# RZT2L register map
Vendor: Renesas Electronics Corporation; Series: RZT; File version: 1.20.00
CPU: other r0p0, little endian, MPU, no FPU, VTOR, 4 interrupt priority bits, 624 interrupts
Registers are 32-bit, read-write, reset 0x0 unless marked. A register's access mark holds for its fields unless they carry their own. Offsets are from the block's base; [hi:lo] are bit positions; {n}, {i} and the like mark numbered series; 'fields as' and 'values as' point back to an identical list.

## CANFD (part 2 of 2)
Base 0x80020000
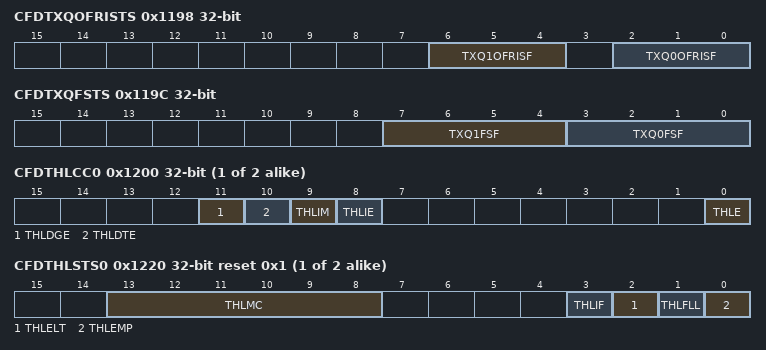
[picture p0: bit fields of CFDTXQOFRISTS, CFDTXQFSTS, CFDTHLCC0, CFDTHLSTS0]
0x1198 CFDTXQOFRISTS ro — TX Queue One Frame RX Interrupt Status Register
  [6:4] TXQ1OFRISF — TXQ One Frame RX Interrupt Status Flag for Channel 1
    0=TXQ One Frame RX Interrupt flag not set; 1=TXQ One Frame RX Interrupt flag set
  [2:0] TXQ0OFRISF — TXQ One Frame RX Interrupt Status Flag for Channel 0
    values as TXQ1OFRISF
0x119C CFDTXQFSTS ro — TX Queue Full Status Register
  [7:4] TXQ1FSF — TXQ Full Status Flag for Channel 1
    0=TXQ Full flag not set; 1=TXQ Full flag set
  [3:0] TXQ0FSF — TXQ Full Status Flag for Channel 0
    0=TXQ Full flag not set; 1=TXQ Full flag set
{0x1200+4i} CFDTHLCC{i} (i=0..1) — TX History List Configuration/Control Register {i}
  [11] THLDGE — TX History List Dedicated Gateway Enable
    0=Not dedicated Gateway FIFO + Gateway TX Queue; 1=Dedicated Gateway FIFO + Gateway TX Queue
  [10] THLDTE — TX History List Dedicated TX Enable
    0=TX FIFO + TX Queue; 1=Flat TX MB + TX FIFO + TX Queue
  [9] THLIM — TX History List Interrupt Mode
    0=Interrupt generated if TX History List level reaches 3/4 of the TX History List depth; 1=Interrupt generated for every successfully stored entry
  [8] THLIE — TX History List Interrupt Enable
    0=TX History List Interrupt disabled; 1=TX History List Interrupt enabled
  [0] THLE — TX History List Enable
    0=TX History List disabled; 1=TX History List enabled
{0x1220+4i} CFDTHLSTS{i} (i=0..1) reset 0x1 — TX History List Status Register {i}
  [13:8] THLMC ro — TX History List Message Count
  [3] THLIF — TX History List Interrupt Flag
    0=TX History List interrupt condition not satisfied; 1=TX History List interrupt condition satisfied
  [2] THLELT — TX History List Entry Lost
    0=No entry lost in TX History List; 1=TX History List entry Lost
  [1] THLFLL ro — TX History List Full
    0=TX History List not full; 1=TX History List full
  [0] THLEMP ro — TX History List Empty
    0=TX History List not empty; 1=TX History List empty
{0x1240+4i} CFDTHLPCTR{i} (i=0..1) wo — TX History List Pointer Control Register {i}
  [7:0] THLPC — TX History List Pointer Control
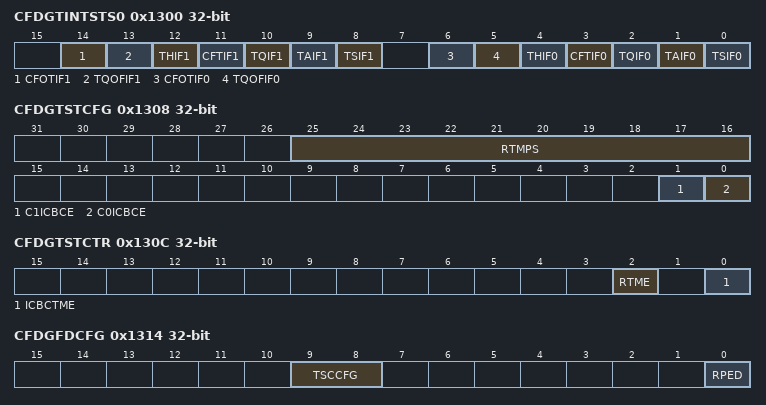
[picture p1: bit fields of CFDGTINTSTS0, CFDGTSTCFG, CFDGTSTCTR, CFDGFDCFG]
0x1300 CFDGTINTSTS0 ro — Global TX Interrupt Status Register 0
  [14] CFOTIF1 — COM FIFO One Frame Transmission Interrupt Flag Channel 1
    0=Channel 1 COM FIFO One Frame Transmission Interrupt flag not set; 1=Channel 1 COM FIFO One Frame Transmission Interrupt flag set
  [13] TQOFIF1 — TX Queue One Frame Transmission Interrupt Flag Channel 1
    0=Channel 1 TX Queue One Frame Transmission Interrupt flag not set; 1=Channel 1 TX Queue One Frame Transmission Interrupt flag set
  [12] THIF1 — TX History List Interrupt Channel 1
    0=Channel 1 TX History List Interrupt flag not set; 1=Channel 1 TX History List Interrupt flag set
  [11] CFTIF1 — COM FIFO TX/GW Mode Interrupt Flag Channel 1
    0=Channel 1 COM FIFO TX/GW Mode Interrupt flag not set; 1=Channel 1 COM FIFO TX/GW Mode Interrupt flag set
  [10] TQIF1 — TX Queue Interrupt Flag Channel 1
    0=Channel 1 TX Queue Interrupt flag not set; 1=Channel 1 TX Queue Interrupt flag set
  [9] TAIF1 — TX Abort Interrupt Flag Channel 1
    0=Channel 1 TX Abort Interrupt flag not set; 1=Channel 1 TX Abort Interrupt flag set
  [8] TSIF1 — TX Successful Interrupt Flag Channel 1
    0=Channel 1 TX Successful Interrupt flag not set; 1=Channel 1 TX Successful Interrupt flag set
  [6] CFOTIF0 — COM FIFO One Frame Transmission Interrupt Flag Channel 0
    0=Channel 0 COM FIFO One Frame Transmission Interrupt flag not set; 1=Channel 0 COM FIFO One Frame Transmission Interrupt flag set
  [5] TQOFIF0 — TX Queue One Frame Transmission Interrupt Flag Channel 0
    0=Channel 0 TX Queue One Frame Transmission Interrupt flag not set; 1=Channel 0 TX Queue One Frame Transmission Interrupt flag set
  [4] THIF0 — TX History List Interrupt Channel 0
    0=Channel 0 TX History List Interrupt flag not set; 1=Channel 0 TX History List Interrupt flag set
  [3] CFTIF0 — COM FIFO TX/GW Mode Interrupt Flag Channel 0
    0=Channel 0 COM FIFO TX/GW Mode Interrupt flag not set; 1=Channel 0 COM FIFO TX/GW Mode Interrupt flag set
  [2] TQIF0 — TX Queue Interrupt Flag Channel 0
    0=Channel 0 TX Queue Interrupt flag not set; 1=Channel 0 TX Queue Interrupt flag set
  [1] TAIF0 — TX Abort Interrupt Flag Channel 0
    0=Channel 0 TX Abort Interrupt flag not set; 1=Channel 0 TX Abort Interrupt flag set
  [0] TSIF0 — TX Successful Interrupt Flag Channel 0
    0=Channel 0 TX Successful Interrupt flag not set; 1=Channel 0 TX Successful Interrupt flag set
0x1308 CFDGTSTCFG — Global Test Configuration Register
  [25:16] RTMPS — RAM Test Mode Page Select
  [1] C1ICBCE — Channel 1 Internal CAN Bus Communication Test Mode Enable
    0=Channel 1 internal CAN bus communication disabled; 1=Channel 1 internal CAN bus communication enabled
  [0] C0ICBCE — Channel 0 Internal CAN Bus Communication Test Mode Enable
    0=Channel 0 internal CAN bus communication disabled; 1=Channel 0 internal CAN bus communication enabled
0x130C CFDGTSTCTR — Global Test Control Register
  [2] RTME — RAM Test Mode Enable
    0=RAM test mode disabled; 1=RAM test mode enabled
  [0] ICBCTME — Internal CAN Bus Communication Test Mode Enable
    0=Internal CAN Bus Communication test mode disabled; 1=Internal CAN Bus Communication test mode enabled
0x1314 CFDGFDCFG — Global FD Configuration Register
  [9:8] TSCCFG — Timestamp Capture Configuration
    0=Timestamp capture at the sample point of SOF (start of frame); 1=Timestamp capture at frame valid indication; 2=Timestamp capture at the sample point of RES bit
  [0] RPED — RES Bit Protocol Exception Disable
    0=Protocol exception event detection enabled; 1=Protocol exception event detection disabled
0x131C CFDGLOCKK wo — Global Lock Key Register
  [15:0] LOCK — Lock Key
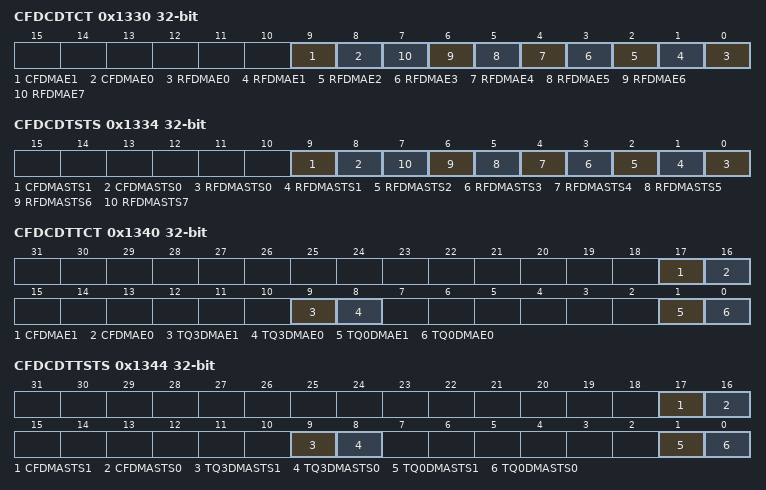
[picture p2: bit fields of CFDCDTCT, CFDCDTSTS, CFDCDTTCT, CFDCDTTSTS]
0x1330 CFDCDTCT — DMA Transfer Control Register
  [all] fields
    0=DMA transfer request disabled; 1=DMA transfer request enabled
  [9] CFDMAE1 — DMA Transfer Enable for Common FIFO 0 of Channel 1
  [8] CFDMAE0 — DMA Transfer Enable for Common FIFO 0 of Channel 0
  [n] RFDMAE{n} (n=0..7) — DMA Transfer Enable for RX FIFO {n}
0x1334 CFDCDTSTS ro — DMA Transfer Status Register
  [all] fields
    0=DMA transfer stopped; 1=DMA transfer on going
  [9] CFDMASTS1 — DMA Transfer Status only for Common FIFO 0 of Channel 1
  [8] CFDMASTS0 — DMA Transfer Status only for Common FIFO 0 of Channel 0
  [n] RFDMASTS{n} (n=0..7) — DMA Transfer Status for RX FIFO {n}
0x1340 CFDCDTTCT — DMA TX Transfer Control Register
  [all] fields
    0=DMA TX transfer request disabled; 1=DMA TX transfer request enabled
  [17] CFDMAE1 — DMA TX Transfer Enable for Common FIFO 2 of Channel 1
  [16] CFDMAE0 — DMA TX Transfer Enable for Common FIFO 2 of Channel 0
  [9] TQ3DMAE1 — DMA TX Transfer Enable for TXQ 3 of Channel 1
  [8] TQ3DMAE0 — DMA TX Transfer Enable for TXQ 3 of Channel 0
  [1] TQ0DMAE1 — DMA TX Transfer Enable for TXQ 0 of Channel 1
  [0] TQ0DMAE0 — DMA TX Transfer Enable for TXQ 0 of Channel 0
0x1344 CFDCDTTSTS ro — DMA TX Transfer Status Register
  [all] fields
    0=DMA TX transfer stopped; 1=DMA TX transfer enabled
  [17] CFDMASTS1 — DMA TX Transfer Status for Common FIFO 2 of Channel 1
  [16] CFDMASTS0 — DMA TX Transfer Status for Common FIFO 2 of Channel 0
  [9] TQ3DMASTS1 — DMA TX Transfer Status for TXQ3 of Channel 1
  [8] TQ3DMASTS0 — DMA TX Transfer Status for TXQ3 of Channel 0
  [1] TQ0DMASTS1 — DMA TX Transfer Status for TXQ0 of Channel 1
  [0] TQ0DMASTS0 — DMA TX Transfer Status for TXQ0 of Channel 0
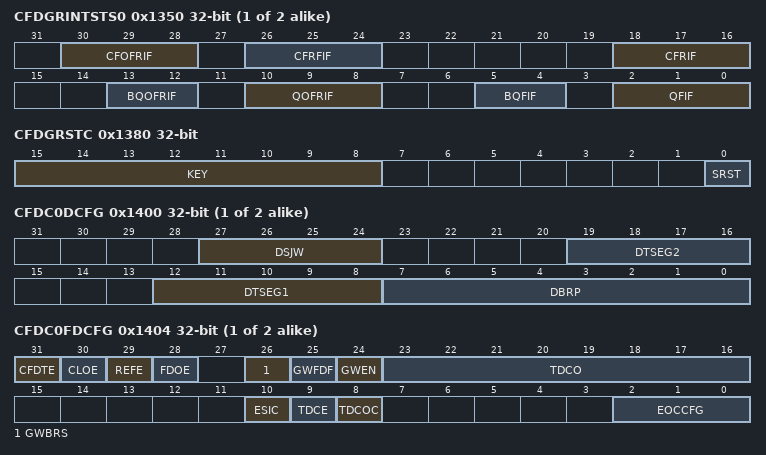
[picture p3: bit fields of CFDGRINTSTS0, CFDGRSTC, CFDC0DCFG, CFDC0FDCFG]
{0x1350+4i} CFDGRINTSTS{i} (i=0..1) ro — Global RX Interrupt Status Register {i}
  [30:28] CFOFRIF — Common FIFO One Frame RX Interrupt Flag Channel n (n = 0, 1)
    0=Corresponding Common FIFO One Frame RX Interrupt flag is not set; 1=Corresponding Common FIFO One Frame RX Interrupt flag is set
  [26:24] CFRFIF — Common FIFO FDC Level Full Interrupt Flag Channel n (n = 0, 1)
    0=Corresponding Common FIFO Full Interrupt flag is not set; 1=Corresponding Common FIFO Full Interrupt flag is set
  [18:16] CFRIF — Common FIFO RX Interrupt Flag Channel n (n = 0, 1)
    0=Corresponding Common FIFO RX Interrupt flag is not set; 1=Corresponding Common FIFO RX Interrupt flag is set
  [13:12] BQOFRIF — Borrowed TXQ One Frame RX Interrupt Flag Channel n (n = 0, 1)
    0=Corresponding TXQ One Frame RX Interrupt flag is not set; 1=Corresponding TXQ One Frame RX Interrupt flag is set
  [10:8] QOFRIF — TXQ One Frame RX Interrupt Flag Channel n (n = 0, 1)
    values as BQOFRIF
  [5:4] BQFIF — Borrowed TXQ Full Interrupt Flag Channel n (n = 0, 1)
    0=Corresponding TXQ Full Interrupt flag is not set; 1=Corresponding TXQ Full Interrupt flag is set
  [2:0] QFIF — TXQ Full Interrupt Flag Channel n (n = 0, 1)
    values as BQFIF
0x1380 CFDGRSTC — Global Reset Control Register
  [15:8] KEY wo — Key Code
  [0] SRST — Software Reset
    0=Normal state; 1=Software reset state
0x1384 CFDGFCMC — Global Flexible CAN Mode Configuration Register
  [0] FLXC0 — Flexible CAN Mode between Channel 0 and Channel 1
    0=Normal mode; 1=Flexible CAN mode
0x138C CFDGFTBAC — Global Flexible Transmission Buffer Assignment Configuration Register
  [3:0] FLXMB0 — Flexible Transmission Buffer Assignment between Channel 0 and Channel 1
    0=0; 1=4; 2=8; 3=12; 4=16; 5=20; 6=24; 7=28; 8=32; other=Others (Setting prohibited)
{0x1400+0x20*i} CFDC{i}DCFG (i=0..1) — Channel {i} Data Bit Rate Configuration Register
  [27:24] DSJW — Data Bit Rate Resynchronization Jump Width Control
  [19:16] DTSEG2 — Data Bit Rate Time Segment 2 Control
  [12:8] DTSEG1 — Data Bit Rate Time Segment 1 Control
  [7:0] DBRP — Data Bit Rate Prescaler Division Ratio Setting
{0x1404+0x20*i} CFDC{i}FDCFG (i=0..1) — Channel {i} CAN-FD Configuration Register
  [31] CFDTE — CAN-FD Frame Distinction Enable
    0=CAN-FD frame distinction disabled; 1=CAN-FD frame distinction enabled
  [30] CLOE — Classical CAN-Only Enable
    0=Classical-only mode disabled; 1=Classical-only mode enabled
  [29] REFE — RX Edge Filter Enable
    0=RX edge filter disabled; 1=RX edge filter enabled
  [28] FDOE — FD-Only Enable
    0=FD-only mode disabled; 1=FD-only mode enabled
  [26] GWBRS — Gateway BRS Configuration Bit
    0=Gateway frame is transmitted with BRS = 0; 1=Gateway frame is transmitted with BRS = 1
  [25] GWFDF — Gateway FDF Configuration Bit
    0=Gateway frame is transmitted as Classical CAN frame; 1=Gateway frame is transmitted as CAN-FD frame
  [24] GWEN — CAN2.0, CAN-FD Multi Gateway Enable
    0=Multi gateway disabled; 1=Multi gateway enabled
  [23:16] TDCO — Transceiver Delay Compensation Offset
  [10] ESIC — Error State Indication Configuration
    0=The ESI bit in the frame represents the error state of the node itself; 1=The ESI bit in the frame represents the error state of the message buffer if the node itself is not in error passive. If the node is in error passive, then the ESI bit is driven by the node itself.
  [9] TDCE — Transceiver Delay Compensation Enable
    0=Transceiver delay compensation disabled; 1=Transceiver delay compensation enabled
  [8] TDCOC — Transmitter Delay Compensation Offset Configuration
    0=Measurement and offset; 1=Offset-only
  [2:0] EOCCFG — Error Occurrence Counter Configuration
    0=All transmit messages and receive messages; 1=All transmit messages; 2=All receive messages; 3=Setting prohibited; 4=Only data phase of transmitted or received CANFD message; 5=Only data phase of transmitted CANFD message; 6=Only data phase of received CANFD message; 7=Setting prohibited
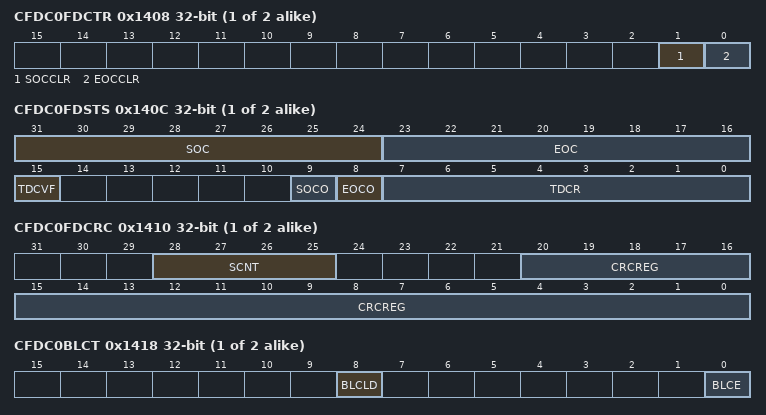
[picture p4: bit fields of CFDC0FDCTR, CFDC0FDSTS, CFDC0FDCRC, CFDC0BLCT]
{0x1408+0x20*i} CFDC{i}FDCTR (i=0..1) — Channel {i} CAN-FD Control Register
  [1] SOCCLR — Successful Occurrence Counter Clear
    0=No successful occurrence counter clear; 1=Clear successful occurrence counter
  [0] EOCCLR — Error Occurrence Counter Clear
    0=No error occurrence counter clear; 1=Clear error occurrence counter
{0x140C+0x20*i} CFDC{i}FDSTS (i=0..1) — Channel {i} CAN-FD Status Register
  [31:24] SOC ro — Successful Occurrence Counter
  [23:16] EOC ro — Error Occurrence Counter
  [15] TDCVF — Transceiver Delay Compensation Violation Flag
    0=Transceiver delay compensation violation has not occurred; 1=Transceiver delay compensation violation has occurred
  [9] SOCO — Successful Occurrence Counter Overflow Flag
    0=Successful occurrence counter has not overflowed; 1=Successful occurrence counter has overflowed
  [8] EOCO — Error Occurrence Counter Overflow Flag
    0=Error occurrence counter has not overflowed; 1=Error occurrence counter has overflowed
  [7:0] TDCR ro — Transceiver Delay Compensation Result
{0x1410+0x20*i} CFDC{i}FDCRC (i=0..1) ro — Channel {i} CAN-FD CRC Register
  [28:25] SCNT — Stuff Bit Count
  [20:0] CRCREG — CRC Register Value
{0x1418+0x20*i} CFDC{i}BLCT (i=0..1) — Channel {i} Bus Load Control Register
  [8] BLCLD wo — Bus Load Counter Load
  [0] BLCE — Bus Load Counter Enable
    0=Bus load counter disabled; 1=Bus load counter enabled
{0x141C+0x20*i} CFDC{i}BLSTS (i=0..1) ro — Channel {i} Bus Load Status Register
  [31:3] BLC — Bus Load Counter Status
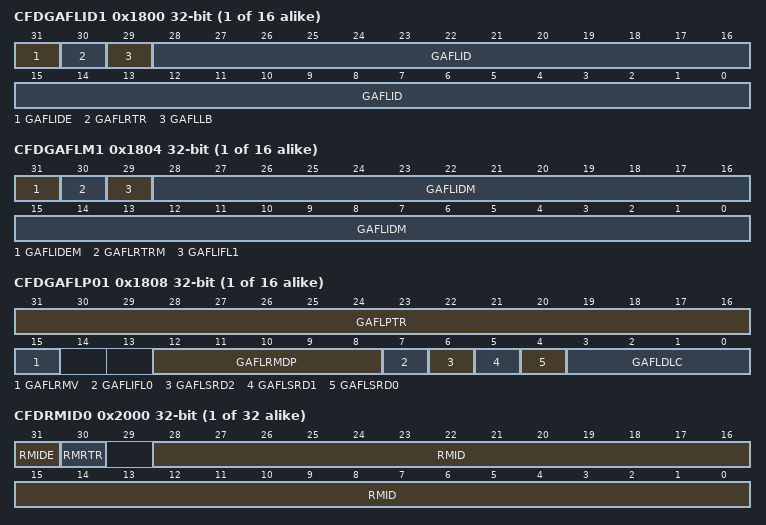
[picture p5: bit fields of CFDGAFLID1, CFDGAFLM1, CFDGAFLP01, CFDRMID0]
{0x17F0+0x10*i} CFDGAFLID{i} (i=1..16) — Global Acceptance Filter List ID Register {i}
  [31] GAFLIDE — Global Acceptance Filter List Entry IDE Field
    0=Standard identifier of rule entry ID is valid for acceptance filtering; 1=Extended identifier of rule entry ID is valid for acceptance filtering
  [30] GAFLRTR — Global Acceptance Filter List Entry RTR Field
    0=Data frame; 1=Remote frame
  [29] GAFLLB — Global Acceptance Filter List Entry Loopback Configuration
    0=Global Acceptance Filter List entry ID for acceptance filtering with attribute RX; 1=Global Acceptance Filter List entry ID for acceptance filtering with attribute TX
  [28:0] GAFLID — Global Acceptance Filter List Entry ID Field
{0x17F4+0x10*i} CFDGAFLM{i} (i=1..16) — Global Acceptance Filter List Mask Register {i}
  [31] GAFLIDEM — Global Acceptance Filter List IDE Mask
    0=IDE bit is not used for ID matching; 1=IDE bit is used for ID matching
  [30] GAFLRTRM — Global Acceptance Filter List Entry RTR Mask
    0=RTR bit is not used for ID matching; 1=RTR bit is used for ID matching
  [29] GAFLIFL1 — Global Acceptance Filter List Information Label 1
  [28:0] GAFLIDM — Global Acceptance Filter List ID Mask Field
{0x17F8+0x10*i} CFDGAFLP0{i} (i=1..16) — Global Acceptance Filter List Pointer 0 Register {i}
  [31:16] GAFLPTR — Global Acceptance Filter List Pointer
  [15] GAFLRMV — Global Acceptance Filter List RX Message Buffer Valid
    0=Single message buffer direction pointer is invalid; 1=Single message buffer direction pointer is valid
  [12:8] GAFLRMDP — Global Acceptance Filter List RX Message Buffer Direction Pointer
  [7] GAFLIFL0 — Global Acceptance Filter List Information Label 0
  [6] GAFLSRD2 — Global Acceptance Filter List Select Routing Destination 2
    0=Routing target is CFIFO2; 1=Routing target is TX Queue 2 instead of CFIFO2
  [5] GAFLSRD1 — Global Acceptance Filter List Select Routing Destination 1
    0=Routing target is CFIFO1; 1=Routing target is TX Queue 1 instead of CFIFO1
  [4] GAFLSRD0 — Global Acceptance Filter List Select Routing Destination 0
    0=Routing target is CFIFO0; 1=Routing target is TX Queue 0 instead of CFIFO0
  [3:0] GAFLDLC — Global Acceptance Filter List DLC Field
{0x17FC+0x10*i} CFDGAFLP1{i} (i=1..16) — Global Acceptance Filter List Pointer 1 Register {i}
  [13:0] GAFLFDP — Global Acceptance Filter List FIFO Direction Pointer
{0x2000+0x80*i} CFDRMID{i} (i=0..31) ro — RX Message Buffer ID Register {i}
  [31] RMIDE — RX Message Buffer IDE Bit
    0=STD-ID is stored; 1=EXT-ID is stored
  [30] RMRTR — RX Message Buffer RTR Bit
    0=Data frame; 1=Remote frame
  [28:0] RMID — RX Message Buffer ID Field
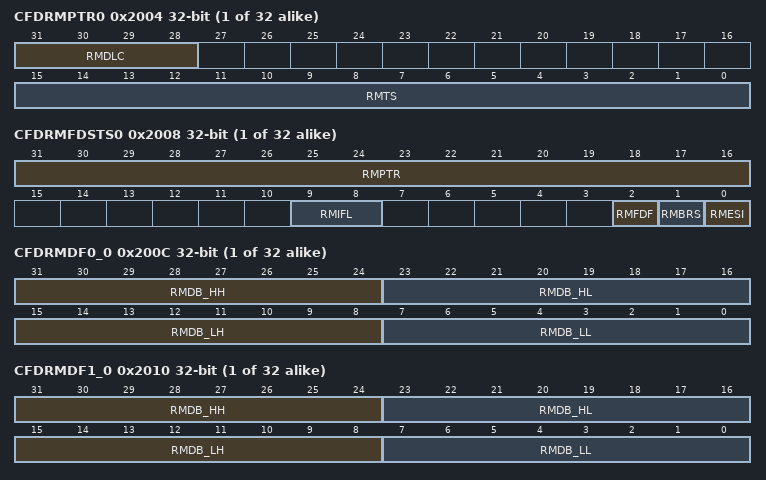
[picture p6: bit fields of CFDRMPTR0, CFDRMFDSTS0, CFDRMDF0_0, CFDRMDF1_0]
{0x2004+0x80*i} CFDRMPTR{i} (i=0..31) — RX Message Buffer Pointer Register
  [31:28] RMDLC — RX Message Buffer DLC Field
  [15:0] RMTS — RX Message Buffer Timestamp Field
{0x2008+0x80*i} CFDRMFDSTS{i} (i=0..31) — RX Message Buffer CAN-FD Status Register
  [31:16] RMPTR — RX Message Buffer Pointer Field
  [9:8] RMIFL — RX Message Buffer Information Label Field
  [2] RMFDF — CAN FD Format bit
    0=Non CAN-FD frame received; 1=CAN-FD frame received
  [1] RMBRS — Bit Rate Switch bit
    0=CAN-FD frame received with no bit rate switch; 1=CAN-FD frame received with bit rate switch
  [0] RMESI — Error State Indicator bit
    0=CAN-FD frame received from error active node; 1=CAN-FD frame received from error passive node
{0x200C+0x80*i} CFDRMDF0_{i} (i=0..31) ro — RX Message Buffer Data Field 0 Register {i}
  [31:24] RMDB_HH — RX Message Buffer Data Byte (4 * p + 3)
  [23:16] RMDB_HL — RX Message Buffer Data Byte (4 * p + 2)
  [15:8] RMDB_LH — RX Message Buffer Data Byte (4 * p + 1)
  [7:0] RMDB_LL — RX Message Buffer Data Byte (4 * p)
{0x2010+0x80*i} CFDRMDF1_{i} (i=0..31) ro — RX Message Buffer Data Field 1 Register {i}
  fields as CFDRMDF0_0
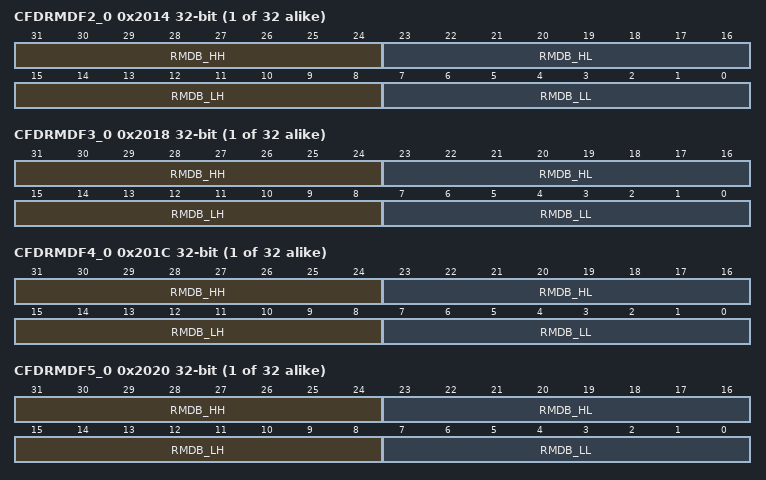
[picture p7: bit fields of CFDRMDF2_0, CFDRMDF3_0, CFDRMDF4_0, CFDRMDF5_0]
{0x2014+0x80*i} CFDRMDF2_{i} (i=0..31) ro — RX Message Buffer Data Field 2 Register {i}
  fields as CFDRMDF0_0
{0x2018+0x80*i} CFDRMDF3_{i} (i=0..31) ro — RX Message Buffer Data Field 3 Register {i}
  fields as CFDRMDF0_0
{0x201C+0x80*i} CFDRMDF4_{i} (i=0..31) ro — RX Message Buffer Data Field 4 Register {i}
  fields as CFDRMDF0_0
{0x2020+0x80*i} CFDRMDF5_{i} (i=0..31) ro — RX Message Buffer Data Field 5 Register {i}
  fields as CFDRMDF0_0
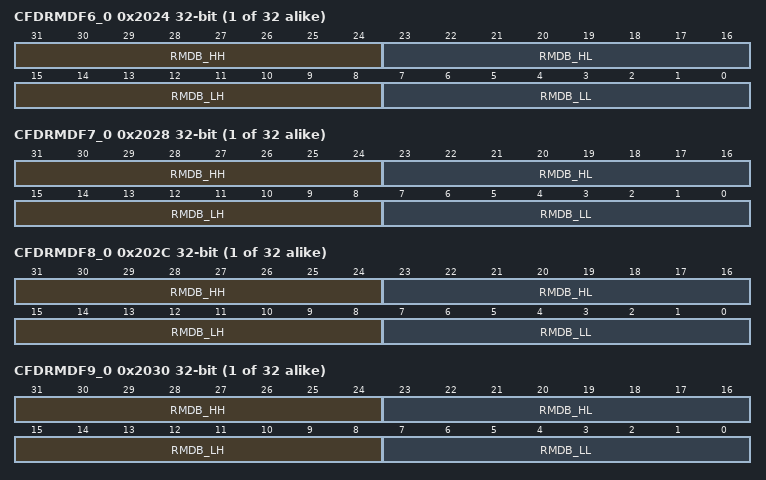
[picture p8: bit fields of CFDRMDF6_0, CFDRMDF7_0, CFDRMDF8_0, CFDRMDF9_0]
{0x2024+0x80*i} CFDRMDF6_{i} (i=0..31) ro — RX Message Buffer Data Field 6 Register {i}
  fields as CFDRMDF0_0
{0x2028+0x80*i} CFDRMDF7_{i} (i=0..31) ro — RX Message Buffer Data Field 7 Register {i}
  fields as CFDRMDF0_0
{0x202C+0x80*i} CFDRMDF8_{i} (i=0..31) ro — RX Message Buffer Data Field 8 Register {i}
  fields as CFDRMDF0_0
{0x2030+0x80*i} CFDRMDF9_{i} (i=0..31) ro — RX Message Buffer Data Field 9 Register {i}
  fields as CFDRMDF0_0
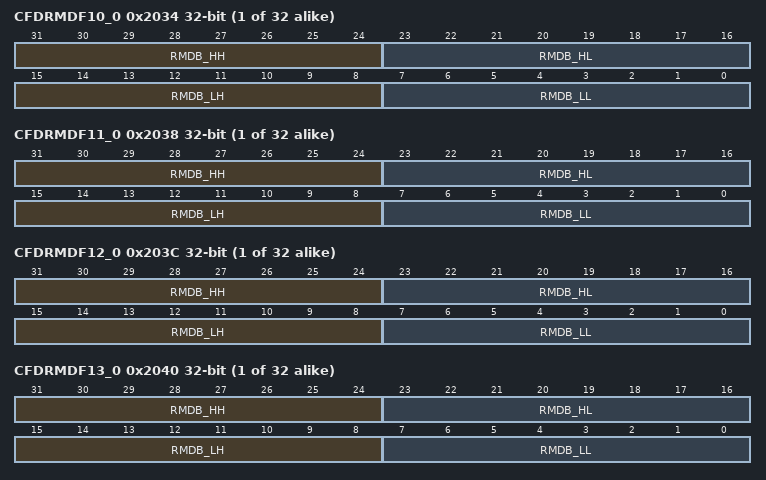
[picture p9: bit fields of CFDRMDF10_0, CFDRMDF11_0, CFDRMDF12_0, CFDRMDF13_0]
{0x2034+0x80*i} CFDRMDF10_{i} (i=0..31) ro — RX Message Buffer Data Field 10 Register {i}
  fields as CFDRMDF0_0
{0x2038+0x80*i} CFDRMDF11_{i} (i=0..31) ro — RX Message Buffer Data Field 11 Register {i}
  fields as CFDRMDF0_0
{0x203C+0x80*i} CFDRMDF12_{i} (i=0..31) ro — RX Message Buffer Data Field 12 Register {i}
  fields as CFDRMDF0_0
{0x2040+0x80*i} CFDRMDF13_{i} (i=0..31) ro — RX Message Buffer Data Field 13 Register {i}
  fields as CFDRMDF0_0
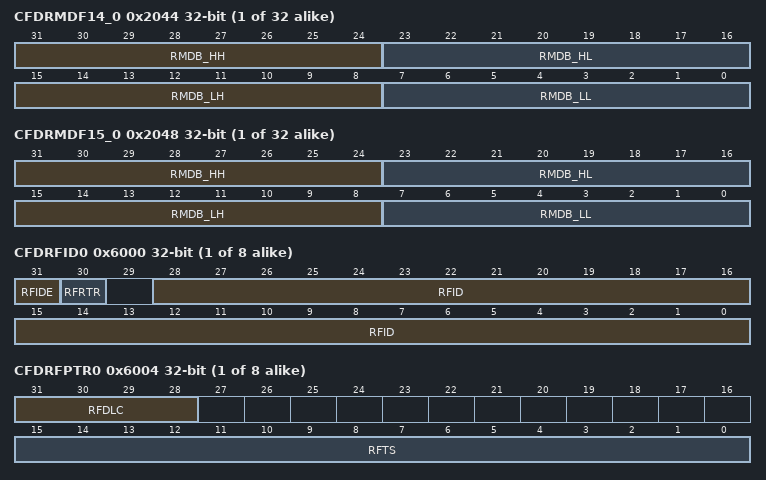
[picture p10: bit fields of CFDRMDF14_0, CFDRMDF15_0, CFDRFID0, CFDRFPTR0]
{0x2044+0x80*i} CFDRMDF14_{i} (i=0..31) ro — RX Message Buffer Data Field 14 Register {i}
  fields as CFDRMDF0_0
{0x2048+0x80*i} CFDRMDF15_{i} (i=0..31) ro — RX Message Buffer Data Field 15 Register {i}
  fields as CFDRMDF0_0
{0x6000+0x80*i} CFDRFID{i} (i=0..7) ro — RX FIFO Access ID Register {i}
  [31] RFIDE — RX FIFO Buffer IDE bit
    0=STD-ID has been received; 1=EXT-ID has been received
  [30] RFRTR — RX FIFO Buffer RTR bit
    0=Data frame; 1=Remote frame
  [28:0] RFID — RX FIFO Buffer ID Field
{0x6004+0x80*i} CFDRFPTR{i} (i=0..7) ro — RX FIFO Access Pointer Register {i}
  [31:28] RFDLC — RX FIFO Buffer DLC Field
  [15:0] RFTS — RX FIFO Timestamp Value
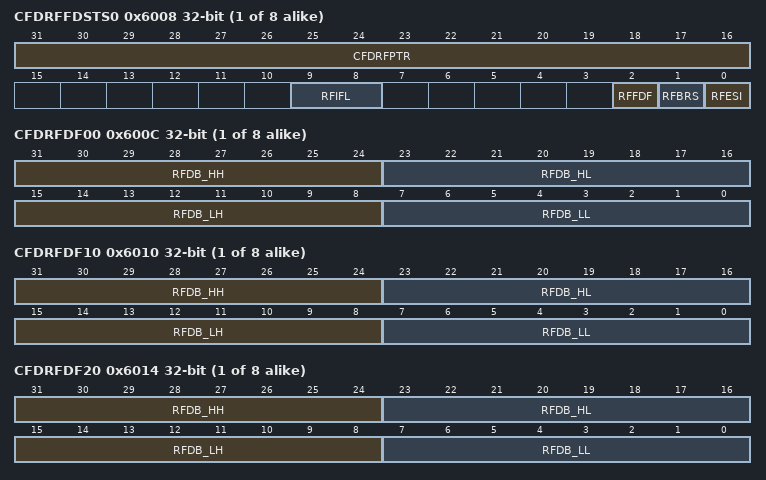
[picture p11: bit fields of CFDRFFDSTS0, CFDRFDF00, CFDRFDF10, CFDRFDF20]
{0x6008+0x80*i} CFDRFFDSTS{i} (i=0..7) ro — RX FIFO Access CAN-FD Status Register {i}
  [31:16] CFDRFPTR — RX FIFO Buffer Pointer Field
  [9:8] RFIFL — RX FIFO Buffer Information Label Field
  [2] RFFDF — CAN FD Format bit
    0=Non CAN-FD frame received; 1=CAN-FD frame received
  [1] RFBRS — Bit Rate Switch bit
    values as CFDRMFDSTS0.RMBRS
  [0] RFESI — Error State Indicator bit
    values as CFDRMFDSTS0.RMESI
{0x600C+0x80*i} CFDRFDF0{i} (i=0..7) ro — RX FIFO Access Data Field 0 Register {i}
  [31:24] RFDB_HH — RX FIFO Buffer Data Byte (4 * p + 3)
  [23:16] RFDB_HL — RX FIFO Buffer Data Byte (4 * p + 2)
  [15:8] RFDB_LH — RX FIFO Buffer Data Byte (4 * p + 1)
  [7:0] RFDB_LL — RX FIFO Buffer Data Byte (4 * p)
{0x6010+0x80*i} CFDRFDF1{i} (i=0..7) ro — RX FIFO Access Data Field 1 Register {i}
  fields as CFDRFDF00
{0x6014+0x80*i} CFDRFDF2{i} (i=0..7) ro — RX FIFO Access Data Field 2 Register {i}
  fields as CFDRFDF00
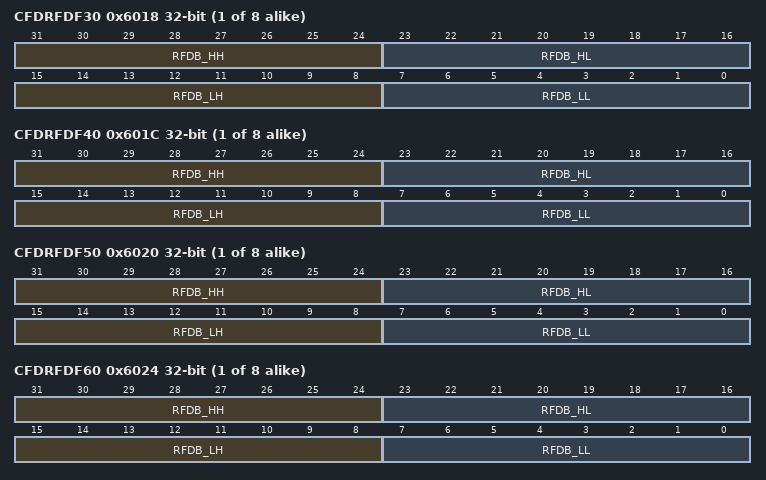
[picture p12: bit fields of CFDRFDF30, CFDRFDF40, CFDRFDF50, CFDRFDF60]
{0x6018+0x80*i} CFDRFDF3{i} (i=0..7) ro — RX FIFO Access Data Field 3 Register {i}
  fields as CFDRFDF00
{0x601C+0x80*i} CFDRFDF4{i} (i=0..7) ro — RX FIFO Access Data Field 4 Register {i}
  fields as CFDRFDF00
{0x6020+0x80*i} CFDRFDF5{i} (i=0..7) ro — RX FIFO Access Data Field 5 Register {i}
  fields as CFDRFDF00
{0x6024+0x80*i} CFDRFDF6{i} (i=0..7) ro — RX FIFO Access Data Field 6 Register {i}
  fields as CFDRFDF00
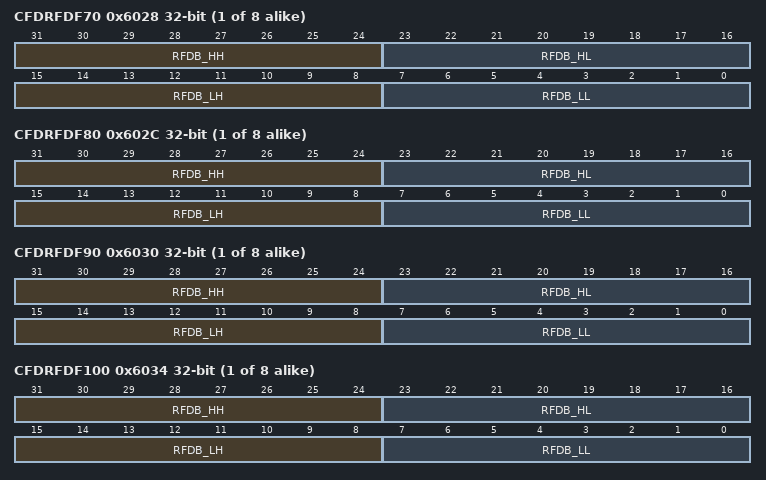
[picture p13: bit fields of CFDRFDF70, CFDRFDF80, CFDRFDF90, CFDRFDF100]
{0x6028+0x80*i} CFDRFDF7{i} (i=0..7) ro — RX FIFO Access Data Field 7 Register {i}
  fields as CFDRFDF00
{0x602C+0x80*i} CFDRFDF8{i} (i=0..7) ro — RX FIFO Access Data Field 8 Register {i}
  fields as CFDRFDF00
{0x6030+0x80*i} CFDRFDF9{i} (i=0..7) ro — RX FIFO Access Data Field 9 Register {i}
  fields as CFDRFDF00
{0x6034+0x80*i} CFDRFDF10{i} (i=0..7) ro — RX FIFO Access Data Field 10 Register {i}
  fields as CFDRFDF00
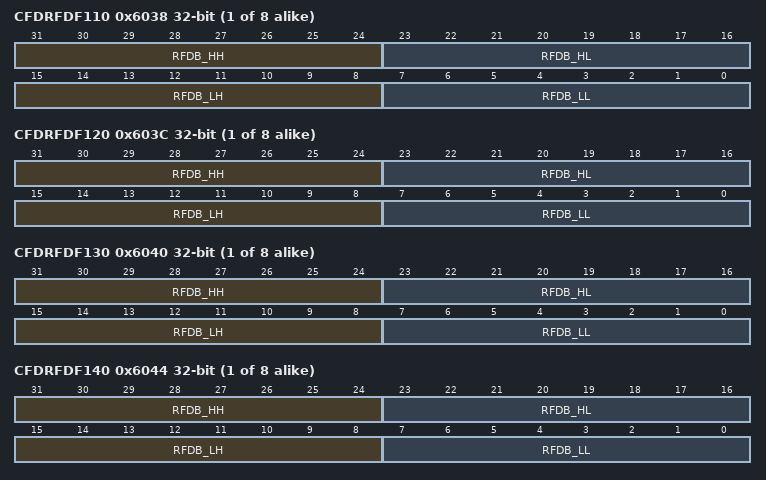
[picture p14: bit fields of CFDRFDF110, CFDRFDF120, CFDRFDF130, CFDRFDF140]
{0x6038+0x80*i} CFDRFDF11{i} (i=0..7) ro — RX FIFO Access Data Field 11 Register 11
  fields as CFDRFDF00
{0x603C+0x80*i} CFDRFDF12{i} (i=0..7) ro — RX FIFO Access Data Field 12 Register {i}
  fields as CFDRFDF00
{0x6040+0x80*i} CFDRFDF13{i} (i=0..7) ro — RX FIFO Access Data Field 13 Register {i}
  fields as CFDRFDF00
{0x6044+0x80*i} CFDRFDF14{i} (i=0..7) ro — RX FIFO Access Data Field 14 Register {i}
  fields as CFDRFDF00
{0x6048+0x80*i} CFDRFDF15{i} (i=0..7) ro — RX FIFO Access Data Field 15 Register {i}
  fields as CFDRFDF00
{0x6400+0x80*i} CFDCFID{i} (i=0..5) — Common FIFO Access ID Register {i}
  [31] CFIDE — Common FIFO Buffer IDE bit
    0=STD-ID is to be transmitted or has been received; 1=EXT-ID is to be transmitted or has been received
  [30] CFRTR — Common FIFO Buffer RTR bit
    0=Data frame; 1=Remote frame
  [29] THLEN — THL Entry Enable
    0=Entry is not to be stored in THL after successful TX; 1=Entry is to be stored in THL after successful TX
  [28:0] CFID — Common FIFO Buffer ID Field
{0x6404+0x80*i} CFDCFPTR{i} (i=0..5) — Common FIFO Access Pointer Register {i}
  [31:28] CFDLC — Common FIFO Buffer DLC Field
  [15:0] CFTS — Common FIFO Timestamp Value
{0x6408+0x80*i} CFDCFFDCSTS{i} (i=0..5) — Common FIFO Access CAN-FD Control/Status Register {i}
  [31:16] CFPTR — Common FIFO Buffer Pointer Field
  [9:8] CFIFL — COMMON FIFO Buffer Information Label Field
  [2] CFFDF — CAN FD Format bit
    0=Non CAN-FD frame received or to transmit; 1=CAN-FD frame received or to transmit
  [1] CFBRS — Bit Rate Switch bit
    0=CAN-FD frame received or to transmit with no bit rate switch; 1=CAN-FD frame received or to transmit with bit rate switch
  [0] CFESI — Error State Indicator bit
    0=CAN-FD frame received or to transmit by error active node; 1=CAN-FD frame received or to transmit by error passive node
{0x640C+0x80*i} CFDCFDF0{i} (i=0..5) — Common FIFO Access Data Field 0 Register {i}
  [31:24] CFDB_HH — Common FIFO Buffer Data Bytes (4 * p + 3)
  [23:16] CFDB_HL — Common FIFO Buffer Data Bytes (4 * p + 2)
  [15:8] CFDB_LH — Common FIFO Buffer Data Bytes (4 * p + 1)
  [7:0] CFDB_LL — Common FIFO Buffer Data Bytes (4 * p)
{0x6410+0x80*i} CFDCFDF1{i} (i=0..5) — Common FIFO Access Data Field 1 Register {i}
  fields as CFDCFDF00
{0x6414+0x80*i} CFDCFDF2{i} (i=0..5) — Common FIFO Access Data Field 2 Register {i}
  fields as CFDCFDF00
{0x6418+0x80*i} CFDCFDF3{i} (i=0..5) — Common FIFO Access Data Field 3 Register {i}
  fields as CFDCFDF00
{0x641C+0x80*i} CFDCFDF4{i} (i=0..5) — Common FIFO Access Data Field 4 Register {i}
  fields as CFDCFDF00
{0x6420+0x80*i} CFDCFDF5{i} (i=0..5) — Common FIFO Access Data Field 5 Register {i}
  fields as CFDCFDF00
{0x6424+0x80*i} CFDCFDF6{i} (i=0..5) — Common FIFO Access Data Field 6 Register {i}
  fields as CFDCFDF00
{0x6428+0x80*i} CFDCFDF7{i} (i=0..5) — Common FIFO Access Data Field 7 Register {i}
  fields as CFDCFDF00
{0x642C+0x80*i} CFDCFDF8{i} (i=0..5) — Common FIFO Access Data Field 8 Register {i}
  fields as CFDCFDF00
{0x6430+0x80*i} CFDCFDF9{i} (i=0..5) — Common FIFO Access Data Field 9 Register {i}
  fields as CFDCFDF00
{0x6434+0x80*i} CFDCFDF10{i} (i=0..5) — Common FIFO Access Data Field 10 Register {i}
  fields as CFDCFDF00
{0x6438+0x80*i} CFDCFDF11{i} (i=0..5) — Common FIFO Access Data Field 11 Register {i}
  fields as CFDCFDF00
{0x643C+0x80*i} CFDCFDF12{i} (i=0..5) — Common FIFO Access Data Field 12 Register {i}
  fields as CFDCFDF00
{0x6440+0x80*i} CFDCFDF13{i} (i=0..5) — Common FIFO Access Data Field 13 Register {i}
  fields as CFDCFDF00
{0x6444+0x80*i} CFDCFDF14{i} (i=0..5) — Common FIFO Access Data Field 14 Register {i}
  fields as CFDCFDF00
{0x6448+0x80*i} CFDCFDF15{i} (i=0..5) — Common FIFO Access Data Field 15 Register {i}
  fields as CFDCFDF00
{0x8000+8i} CFDTHLACC0{i} (i=0..1) ro — Channel {i} TX History List Access Register 0
  [31:16] TMTS — Transmit Timestamp
  [15] TGW — Transmit Gateway Buffer Indication
    0=No transmission from gateway; 1=Transmission from gateway
  [9:3] BN — Buffer Number
  [2:0] BT — Buffer Type
    1=Flat TX message buffer; 2=TX FIFO message buffer number and gateway FIFO message number; 4=TX Queue message buffer number; other=Others (Setting prohibited)
{0x8004+8i} CFDTHLACC1{i} (i=0..1) ro — Channel {i} TX History List Access Register 1
  [17:16] TIFL — Transmit Information Label
  [15:0] TID — Transmit ID
{0x8400+4i} CFDRPGACC{i} (i=0..63) — RAM Test Page Access Register {i}
  [31:0] RDTA — RAM Data Test Access
{0x10000+0x80*i} CFDTMID{i} (i=0..127) — TX Message Buffer ID Register {i}
  [31] TMIDE — TX Message Buffer IDE bit
    0=STD-ID is transmitted; 1=EXT-ID is transmitted
  [30] TMRTR — TX Message Buffer RTR bit
    0=Data frame; 1=Remote frame
  [29] THLEN — Tx History List Entry
    0=Entry not stored in THL after successful TX; 1=Entry stored in THL after successful TX
  [28:0] TMID — TX Message Buffer ID Field
{0x10004+0x80*i} CFDTMPTR{i} (i=0..127) — TX Message Buffer Pointer Register {i}
  [31:28] TMDLC — TX Message Buffer DLC Field
{0x10008+0x80*i} CFDTMFDCTR{i} (i=0..127) — TX Message Buffer CAN-FD Control Register {i}
  [31:16] TMPTR — TX Message Buffer Pointer Field
  [9:8] TMIFL — TX Message Buffer Information Label Field
  [2] TMFDF — CAN FD Format bit
    0=Non CAN-FD frame to transmit; 1=CAN-FD frame to transmit
  [1] TMBRS — Bit Rate Switch bit
    0=CAN-FD frame to transmit with no bit rate switch; 1=CAN-FD frame to transmit with bit rate switch
  [0] TMESI — Error State Indicator bit
    0=CAN-FD frame to transmit by error active node; 1=CAN-FD frame to transmit by error passive node
{0x1000C+0x80*i} CFDTMDF0_{i} (i=0..127) — TX Message Buffer Data Field 0 Register {i}
  [31:24] TMDB_HH — TX Message Buffer Data Byte (4 * p + 3)
  [23:16] TMDB_HL — TX Message Buffer Data Byte (4 * p + 2)
  [15:8] TMDB_LH — TX Message Buffer Data Byte (4 * p + 1)
  [7:0] TMDB_LL — TX Message Buffer Data Byte (4 * p)
{0x10010+0x80*i} CFDTMDF1_{i} (i=0..127) — TX Message Buffer Data Field 1 Register {i}
  fields as CFDTMDF0_0
{0x10014+0x80*i} CFDTMDF2_{i} (i=0..127) — TX Message Buffer Data Field 2 Register {i}
  fields as CFDTMDF0_0
{0x10018+0x80*i} CFDTMDF3_{i} (i=0..127) — TX Message Buffer Data Field 3 Register {i}
  fields as CFDTMDF0_0
{0x1001C+0x80*i} CFDTMDF4_{i} (i=0..127) — TX Message Buffer Data Field 4 Register {i}
  fields as CFDTMDF0_0
{0x10020+0x80*i} CFDTMDF5_{i} (i=0..127) — TX Message Buffer Data Field 5 Register {i}
  fields as CFDTMDF0_0
{0x10024+0x80*i} CFDTMDF6_{i} (i=0..127) — TX Message Buffer Data Field 6 Register {i}
  fields as CFDTMDF0_0
{0x10028+0x80*i} CFDTMDF7_{i} (i=0..127) — TX Message Buffer Data Field 7 Register {i}
  fields as CFDTMDF0_0
{0x1002C+0x80*i} CFDTMDF8_{i} (i=0..127) — TX Message Buffer Data Field 8 Register {i}
  fields as CFDTMDF0_0
{0x10030+0x80*i} CFDTMDF9_{i} (i=0..127) — TX Message Buffer Data Field 9 Register {i}
  fields as CFDTMDF0_0
{0x10034+0x80*i} CFDTMDF10_{i} (i=0..127) — TX Message Buffer Data Field 10 Register {i}
  fields as CFDTMDF0_0
{0x10038+0x80*i} CFDTMDF11_{i} (i=0..127) — TX Message Buffer Data Field 11 Register {i}
  fields as CFDTMDF0_0
{0x1003C+0x80*i} CFDTMDF12_{i} (i=0..127) — TX Message Buffer Data Field 12 Register {i}
  fields as CFDTMDF0_0
{0x10040+0x80*i} CFDTMDF13_{i} (i=0..127) — TX Message Buffer Data Field 13 Register {i}
  fields as CFDTMDF0_0
{0x10044+0x80*i} CFDTMDF14_{i} (i=0..127) — TX Message Buffer Data Field 14 Register {i}
  fields as CFDTMDF0_0
{0x10048+0x80*i} CFDTMDF15_{i} (i=0..127) — TX Message Buffer Data Field 15 Register {i}
  fields as CFDTMDF0_0
